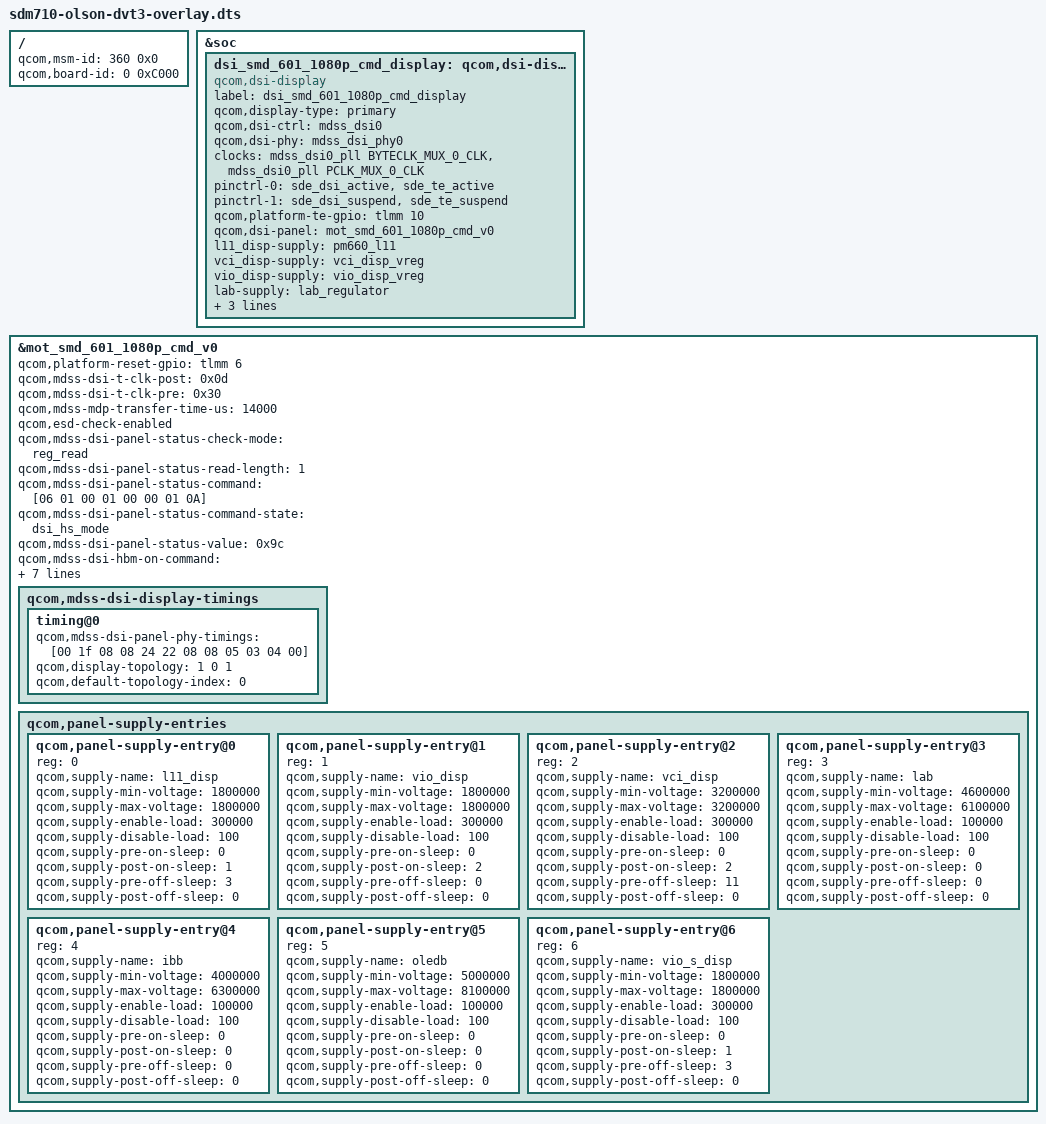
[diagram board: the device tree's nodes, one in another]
/* Copyright (c) 2018, The Linux Foundation. All rights reserved.
 *
 * This program is free software; you can redistribute it and/or modify
 * it under the terms of the GNU General Public License version 2 and
 * only version 2 as published by the Free Software Foundation.
 *
 * This program is distributed in the hope that it will be useful,
 * but WITHOUT ANY WARRANTY; without even the implied warranty of
 * MERCHANTABILITY or FITNESS FOR A PARTICULAR PURPOSE.  See the
 * GNU General Public License for more details.
 */

/dts-v1/;
/plugin/;

#include "sdm710-olson-common-overlay.dtsi"
#include "dsi-panel-mot-smd-601-1080p-olson-cmd.dtsi"

/ {
	qcom,msm-id = <360 0x0>;
	qcom,board-id = <0 0xC000>;
};

/*
 * Olson HW rev DVT3 specific changes go here
 */
&soc {
	dsi_smd_601_1080p_cmd_display: qcom,dsi-display@18 {
		compatible = "qcom,dsi-display";
		label = "dsi_smd_601_1080p_cmd_display";
		qcom,display-type = "primary";

		qcom,dsi-ctrl = <&mdss_dsi0>;
		qcom,dsi-phy = <&mdss_dsi_phy0>;
		clocks = <&mdss_dsi0_pll BYTECLK_MUX_0_CLK>,
			<&mdss_dsi0_pll PCLK_MUX_0_CLK>;
		clock-names = "src_byte_clk", "src_pixel_clk";

		pinctrl-names = "panel_active", "panel_suspend";
		pinctrl-0 = <&sde_dsi_active &sde_te_active>;
		pinctrl-1 = <&sde_dsi_suspend &sde_te_suspend>;
		qcom,platform-te-gpio = <&tlmm 10 0>;
		qcom,dsi-panel = <&mot_smd_601_1080p_cmd_v0>;
		l11_disp-supply = <&pm660_l11>;
		vci_disp-supply = <&vci_disp_vreg>;
		vio_disp-supply = <&vio_disp_vreg>;
		lab-supply = <&lab_regulator>;
		ibb-supply = <&ibb_regulator>;
		oledb-supply = <&pm660a_oledb>;
		vio_s_disp-supply = <&vio_disp_sub_vreg>;
	};
};

&mot_smd_601_1080p_cmd_v0 {
	qcom,platform-reset-gpio = <&tlmm 6 0>;
	qcom,mdss-dsi-t-clk-post = <0x0d>;
	qcom,mdss-dsi-t-clk-pre = <0x30>;
	qcom,mdss-mdp-transfer-time-us = <14000>;

	/* Enable ESD checking */
	qcom,esd-check-enabled;
	qcom,mdss-dsi-panel-status-check-mode = "reg_read";
	qcom,mdss-dsi-panel-status-read-length = <1>;
	qcom,mdss-dsi-panel-status-command = [06 01 00 01 00 00 01 0A];
	qcom,mdss-dsi-panel-status-command-state = "dsi_hs_mode";
	qcom,mdss-dsi-panel-status-value = <0x9c>;

	/* MOT panel params */
	qcom,mdss-dsi-hbm-on-command = [15 01 00 00 00 00 02 53 e0];
	qcom,mdss-dsi-hbm-off-command = [15 01 00 00 00 00 02 53 20];
	qcom,mdss-dsi-acl-on-command = [15 01 00 00 00 00 02 55 03];
	qcom,mdss-dsi-acl-off-command = [15 01 00 00 00 00 02 55 00];

	qcom,mdss-dsi-display-timings {
		timing@0{
			qcom,mdss-dsi-panel-phy-timings = [00 1f 08 08 24 22 08
							08 05 03 04 00];
			qcom,display-topology = <1 0 1>;
			qcom,default-topology-index = <0>;
		};
	};

	qcom,panel-supply-entries {
		#address-cells = <1>;
		#size-cells = <0>;

		qcom,panel-supply-entry@0 {
			reg = <0>;
			qcom,supply-name = "l11_disp";
			qcom,supply-min-voltage = <1800000>;
			qcom,supply-max-voltage = <1800000>;
			qcom,supply-enable-load = <300000>;
			qcom,supply-disable-load = <100>;
			qcom,supply-pre-on-sleep = <0>;
			qcom,supply-post-on-sleep = <1>;
			qcom,supply-pre-off-sleep = <3>;
			qcom,supply-post-off-sleep = <0>;
		};

		qcom,panel-supply-entry@1 {
			reg = <1>;
			qcom,supply-name = "vio_disp";
			qcom,supply-min-voltage = <1800000>;
			qcom,supply-max-voltage = <1800000>;
			qcom,supply-enable-load = <300000>;
			qcom,supply-disable-load = <100>;
			qcom,supply-pre-on-sleep = <0>;
			qcom,supply-post-on-sleep = <2>;
			qcom,supply-pre-off-sleep = <0>;
			qcom,supply-post-off-sleep = <0>;
		};

		qcom,panel-supply-entry@2 {
			reg = <2>;
			qcom,supply-name = "vci_disp";
			qcom,supply-min-voltage = <3200000>;
			qcom,supply-max-voltage = <3200000>;
			qcom,supply-enable-load = <300000>;
			qcom,supply-disable-load = <100>;
			qcom,supply-pre-on-sleep = <0>;
			qcom,supply-post-on-sleep = <2>;
			qcom,supply-pre-off-sleep = <11>;
			qcom,supply-post-off-sleep = <0>;
		};

		qcom,panel-supply-entry@3 {
			reg = <3>;
			qcom,supply-name = "lab";
			qcom,supply-min-voltage = <4600000>;
			qcom,supply-max-voltage = <6100000>;
			qcom,supply-enable-load = <100000>;
			qcom,supply-disable-load = <100>;
			qcom,supply-pre-on-sleep = <0>;
			qcom,supply-post-on-sleep = <0>;
			qcom,supply-pre-off-sleep = <0>;
			qcom,supply-post-off-sleep = <0>;
		};

		qcom,panel-supply-entry@4 {
			reg = <4>;
			qcom,supply-name = "ibb";
			qcom,supply-min-voltage = <4000000>;
			qcom,supply-max-voltage = <6300000>;
			qcom,supply-enable-load = <100000>;
			qcom,supply-disable-load = <100>;
			qcom,supply-pre-on-sleep = <0>;
			qcom,supply-post-on-sleep = <0>;
			qcom,supply-pre-off-sleep = <0>;
			qcom,supply-post-off-sleep = <0>;
		};

		qcom,panel-supply-entry@5 {
			reg = <5>;
			qcom,supply-name = "oledb";
			qcom,supply-min-voltage = <5000000>;
			qcom,supply-max-voltage = <8100000>;
			qcom,supply-enable-load = <100000>;
			qcom,supply-disable-load = <100>;
			qcom,supply-pre-on-sleep = <0>;
			qcom,supply-post-on-sleep = <0>;
			qcom,supply-pre-off-sleep = <0>;
			qcom,supply-post-off-sleep = <0>;
		};

		qcom,panel-supply-entry@6 {
			reg = <6>;
			qcom,supply-name = "vio_s_disp";
			qcom,supply-min-voltage = <1800000>;
			qcom,supply-max-voltage = <1800000>;
			qcom,supply-enable-load = <300000>;
			qcom,supply-disable-load = <100>;
			qcom,supply-pre-on-sleep = <0>;
			qcom,supply-post-on-sleep = <1>;
			qcom,supply-pre-off-sleep = <3>;
			qcom,supply-post-off-sleep = <0>;
		};
	};
};
